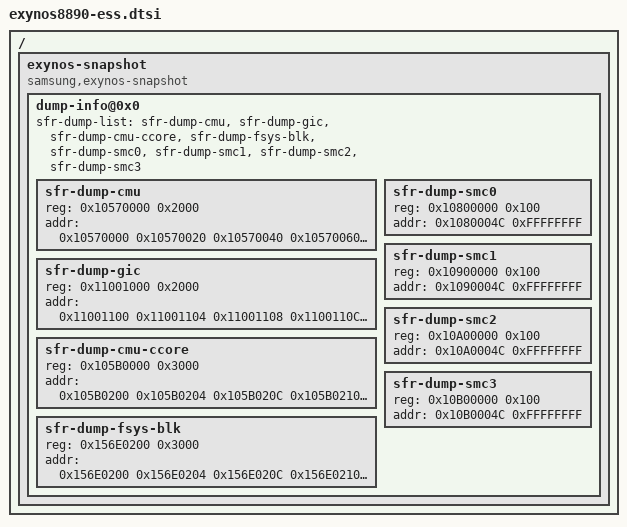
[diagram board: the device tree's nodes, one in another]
/*
 * SAMSUNG EXYNOS8890 SoC device tree source
 *
 * Copyright (c) 2015 Samsung Electronics Co., Ltd.
 *		http://www.samsung.com
 *
 * SAMSUNG EXYNOS8890 SoC device nodes are listed in this file.
 * EXYNOS8890 based board files can include this file and provide
 * values for board specfic bindings.
 *
 * This program is free software; you can redistribute it and/or modify
 * it under the terms of the GNU General Public License version 2 as
 * published by the Free Software Foundation.
 */

/ {
	exynos-snapshot {
		compatible = "samsung,exynos-snapshot";
		dump-info@0x0 {
			sfr-dump-list = "sfr-dump-cmu", "sfr-dump-gic", "sfr-dump-cmu-ccore", "sfr-dump-fsys-blk",
					"sfr-dump-smc0", "sfr-dump-smc1", "sfr-dump-smc2", "sfr-dump-smc3";
			#address-cells = <1>;
			#size-cells = <1>;

			sfr-dump-cmu {
					reg = <0x10570000 0x2000>;
					addr = <0x10570000 0x10570020 0x10570040 0x10570060 0x10570080 0x105700A0 0x105700C0
						0x105700E0 0x10570100 0x10570104 0x1057010C 0x10570120 0x10570124 0x1057012C
						0x10570140 0x10570144 0x1057014C 0x10570160 0x10570164 0x1057016C 0x10570180
						0x10570184 0x1057018C 0x105701A0 0x105701A4 0x105701AC 0x105701C0 0x105701C4
						0x105701C8 0x105701E0 0x105701E4 0x105701EC 0x10570200 0x10570204 0x10570208
						0x1057020C 0x10570210 0x10570214 0x10570218 0x1057021C 0x10570220 0x10570224
						0x10570228 0x1057022C 0x10570230 0x10570234 0x10570240 0x10570244 0x10570248
						0x1057024C 0x10570250 0x10570254 0x10570258 0x1057025C 0x10570260 0x10570264
						0x10570268 0x1057026C 0x10570270 0x10570274 0x10570278 0x1057027C 0x10570280
						0x10570284 0x10570288 0x1057028C 0x10570290 0x10570294 0x10570298 0x1057029C
						0x105702A0 0x105702A4 0x105702A8 0x105702AC 0x105702B0 0x105702B4 0x105702B8
						0x105702BC 0x105702C0 0x105702C4 0x105702C8 0x105702CC 0x105702D0 0x105702D4
						0x105702D8 0x105702DC 0x105702E0 0x105702E4 0x105702E8 0x105702EC 0x105702F0
						0x105702F4 0x105702F8 0x105702FC 0x10570300 0x10570304 0x10570308 0x1057030C
						0x10570310 0x10570314 0x10570318 0x1057031C 0x10570320 0x10570324 0x10570328
						0x1057032C 0x10570330 0x10570334 0x10570338 0x1057033C 0x10570340 0x10570344
						0x10570348 0x1057034C 0x10570350 0x10570354 0x10570358 0x1057035C 0x10570360
						0x10570364 0x10570368 0x1057036C 0x10570370 0x10570374 0x10570378 0x10570380
						0x10570384 0x10570388 0x1057038C 0x10570390 0x105703A0 0x105703A4 0x105703A8
						0x105703AC 0x105703B0 0x105703B4 0x105703B8 0x105703BC 0x105703C0 0x105703C4
						0x105703C8 0x105703CC 0x105703D0 0x105703D4 0x105703D8 0x105703DC 0x105703E0
						0x105703E4 0x105703E8 0x105703EC 0x105703F0 0x105703F4 0x105703F8 0x105703FC
						0x10570400 0x10570404 0x10570408 0x1057040C 0x10570410 0x10570414 0x10570418
						0x1057041C 0x10570420 0x10570424 0x10570428 0x1057042C 0x10570430 0x10570434
						0x10570438 0x1057043C 0x10570440 0x10570444 0x10570448 0x1057044C 0x10570450
						0x10570454 0x10570458 0x1057045C 0x10570460 0x10570464 0x10570468 0x1057046C
						0x10570470 0x10570474 0x10570478 0x1057047C 0x10570480 0x10570484 0x10570488
						0x1057048C 0x10570490 0x10570494 0x10570498 0x1057049C 0x105704A0 0x105704A4
						0x105704A8 0x105704AC 0x105704B0 0x105704B4 0x105704B8 0x105704BC 0x105704C0
						0x105704C4 0x105704C8 0x105704CC 0x105704D0 0x105704D4 0x105704D8 0x105704DC
						0x105704F0 0x105704F4 0x105704F8 0x105704FC 0x10570500 0x10570504 0x10570508
						0x1057050C 0x10570510 0x10570514 0x10570518 0x1057051C 0x10570520 0x10570524
						0x10570528 0x1057052C 0x10570530 0x10570534 0x10570540 0x10570544 0x10570548
						0x1057054C 0x10570550 0x10570554 0x10570558 0x1057055C 0x10570560 0x10570564
						0x10570568 0x1057056C 0x10570570 0x10570574 0x10570578 0x1057057C 0x10570580
						0x10570584 0x10570588 0x1057058C 0x10570590 0x10570594 0x10570598 0x1057059C
						0x105705A0 0x105705A4 0x105705A8 0x105705AC 0x105705B0 0x105705B4 0x105705B8
						0x105705BC 0x105705C0 0x105705C4 0x105705C8 0x105705CC 0x105705D0 0x105705D4
						0x105705D8 0x105705DC 0x105705E0 0x105705E4 0x105705E8 0x105705EC 0x105705F0
						0x105705F4 0x105705F8 0x105705FC 0x10570600 0x10570604 0x10570608 0x1057060C
						0x10570610 0x10570614 0x10570618 0x1057061C 0x10570620 0x10570624 0x10570628
						0x1057062C 0x10570630 0x10570634 0x10570638 0x1057063C 0x10570640 0x10570644
						0x10570648 0x1057064C 0x10570650 0x10570654 0x10570658 0x1057065C 0x10570660
						0x10570664 0x10570668 0x1057066C 0x10570670 0x10570674 0x10570678 0x10570680
						0x10570684 0x10570688 0x1057068C 0x10570690 0x10570800 0x10570804 0x10570808
						0x1057080C 0x10570810 0x10570814 0x10570818 0x1057081C 0x10570820 0x10570824
						0x10570828 0x1057082C 0x10570830 0x10570834 0x10570838 0x1057083C 0x10570840
						0x10570844 0x10570848 0x1057084C 0x10570850 0x10570854 0x10570858 0x1057085C
						0x10570860 0x10570864 0x10570868 0x1057086C 0x10570870 0x10570874 0x10570878
						0x1057087C 0x10570880 0x10570884 0x10570888 0x1057088C 0x10570890 0x10570894
						0x10570898 0x1057089C 0x105708A0 0x105708A4 0x105708A8 0x105708AC 0x105708B0
						0x10570900 0x10570904 0x10570908 0x1057090C 0x10570910 0x10570914 0x10570918
						0x1057091C 0x10570920 0x10570924 0x10570928 0x1057092C 0x10570930 0x10570934
						0x10570938 0x1057093C 0x10570940 0x10570944 0x10570948 0x1057094C 0x10570950
						0x10570954 0x10570958 0x1057095C 0x10570960 0x10570964 0x10570968 0x1057096C
						0x10570970 0x10570974 0x10570978 0x1057097C 0x10570980 0x10570984 0x10570990
						0x10570994 0x10570998 0x1057099C 0x105709A0 0x10570B00 0x10570B04 0x10570B08
						0x10570B0C 0x10570B10 0x10570B14 0x10570B18 0x10570B1C 0x10570B20 0x10570B24
						0x10570B28 0x10570B2C 0x10570B30 0x10570B34 0x10570B38 0x10570B3C 0x10570B40
						0x10570B44 0x10570B48 0x10570B4C 0x10570B50 0x10570B54 0x10570B58 0x10570B5C
						0x10570C00 0x10570C04 0x10570C10 0x10570C14 0x10570C20 0x10570C24 0x10570C30
						0x10570C34 0x10570C38 0x10570C3C 0x10570D00 0x10570D0C 0x10570D10 0x10570E00
						0x10570F04 0x10570F10 0x10570F14 0x10570F18 0x10570F1C 0x10570F20 0x10570F24
						0x10570F28 0x10570F2C 0x10570F30 0x10570F40 0x10570F44 0x10570F48 0x10570F4C
						0x10570F50 0x10570F54 0x10570F58 0x10570F5C 0x10570F60 0x10570F80 0x10571000
						0x10571004 0x10571008 0x1057100C 0x10571010 0x10571014 0x10571018 0x1057101C
						0x10571020 0x10571024 0x10571028 0x1057102C 0x10571030 0x10571034 0x10571060
						0x10571080 0x10571084 0x10571088 0x1057108C 0x10571090 0x10571094 0x10571098
						0x1057109C 0x10571100 0x10571104 0x10571108 0x1057110C 0xFFFFFFFF>;
			};

			sfr-dump-gic {
					reg = <0x11001000 0x2000>;
					addr = <0x11001100 0x11001104 0x11001108 0x1100110C 0x11001110 0x11001114 0x11001118 0x1100111C
						0x11001120 0x11001124 0x11001128 0x1100112C 0x11001130 0x11001134 0x11001138 0x1100113C
						0x11001200 0x11001204 0x11001208 0x1100120C 0x11001210 0x11001214 0x11001218 0x1100121C
						0x11001220 0x11001224 0x11001228 0x1100122C 0x11001230 0x11001234 0x11001238 0x1100123C
						0x11001300 0x11001304 0x11001308 0x1100130C 0x11001310 0x11001314 0x11001318 0x1100131C
						0x11001320 0x11001324 0x11001328 0x1100132C 0x11001330 0x11001334 0x11001338 0x1100133C
						0xFFFFFFFF>;
			};

			sfr-dump-cmu-ccore {
					reg = <0x105B0000 0x3000>;
					addr = <0x105B0200 0x105B0204 0x105B020C 0x105B0210 0x105B0800 0x105B0804 0x105B0808 0x105B080C
						0x105B1800 0x105B1804 0x105B1808 0x105B180C 0x105B1810 0x105B1C00 0x105B1C04 0x105B1C08
						0x105B1C0C 0x105B1C10 0x105B1C14 0x105B1C18 0x105B1C1C 0x105B1C20 0x105B1C24 0x105B2000
						0x105B2004 0x105B2008 0x105B200C 0x105B2010 0x105B2014 0x105B2018 0x105B201C 0x105B2020
						0x105B2024 0x105B2028 0x105B202C 0x105B2030 0x105B2034 0x105B2038 0x105B203C 0x105B2040
						0x105B2044 0x105B2048 0xFFFFFFFF>;
			};

			sfr-dump-fsys-blk {
					reg = <0x156E0200 0x3000>;
					addr = <0x156E0200 0x156E0204 0x156E020C 0x156E0210 0x156E0214 0x156E0218 0x156E0220 0x156E0224
						0x156E0230 0x156E0234 0x156E0238 0x156E023C 0x156E0240 0x156E0244 0x156E0400 0x156E0630
						0x156E0634 0x156E0638 0x156E063C 0x156E0640 0x156E0644 0x156E1800 0x156E1824 0x156E1844
						0x156E1848 0x156E184C 0x156E185C 0x156E1860 0x156E186C 0x156E1870 0x156E1874 0x156E1878
						0x156E187C 0x156E1880 0x156E1C00 0x156E1C04 0x156E1C08 0x156E1C0C 0x156E1C10 0x156E1C24
						0x156E1C44 0x156E1C48 0x156E1C4C 0x156E1C5C 0x156E1C60 0x156E1C6C 0x156E1C70 0x156E1C74
						0x156E1C78 0x156E1C7C 0x156E1C80 0x156E2000 0x156E2004 0x156E2008 0x156E200C 0x156E2010
						0x156E2014 0x156E2018 0x156E201C 0x156E2020 0x156E2024 0x156E2028 0x156E202C 0x156E241C
						0x156E2420 0x156E2424 0x156E2428 0x156E242C 0x156E2430 0x156E2434 0x156E2438 0x156E243C
						0x156E2440 0x156E2444 0xFFFFFFFF>;
			};

			sfr-dump-smc0 {
					reg = <0x10800000 0x100>;
					addr = <0x1080004C 0xFFFFFFFF>;
			};

			sfr-dump-smc1 {
					reg = <0x10900000 0x100>;
					addr = <0x1090004C 0xFFFFFFFF>;
			};

			sfr-dump-smc2 {
					reg = <0x10A00000 0x100>;
					addr = <0x10A0004C 0xFFFFFFFF>;
			};

			sfr-dump-smc3 {
					reg = <0x10B00000 0x100>;
					addr = <0x10B0004C 0xFFFFFFFF>;
			};


		};
	};
};
